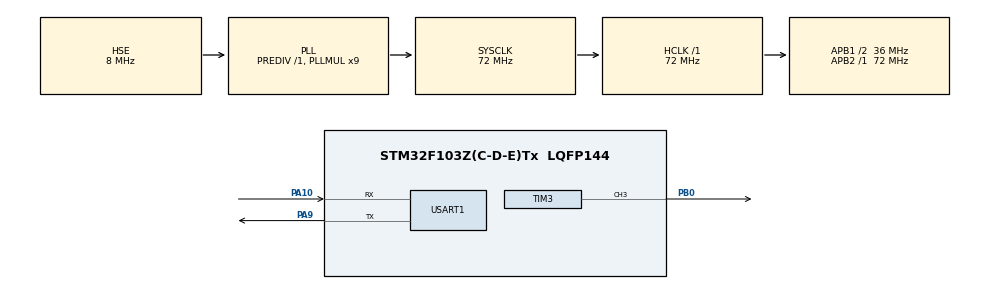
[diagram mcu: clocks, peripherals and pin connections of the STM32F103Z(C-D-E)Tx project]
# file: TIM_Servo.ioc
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Mcu.Family=STM32F1
Mcu.Name=STM32F103Z(C-D-E)Tx
Mcu.Package=LQFP144
NVIC.PriorityGroup=NVIC_PRIORITYGROUP_4
OSC_IN.Mode=HSE-External-Oscillator
OSC_IN.Signal=RCC_OSC_IN
OSC_OUT.Mode=HSE-External-Oscillator
OSC_OUT.Signal=RCC_OSC_OUT
PA10.Mode=Asynchronous
PA10.Signal=USART1_RX
PA13.Mode=Serial_Wire
PA13.Signal=SYS_JTMS-SWDIO
PA14.Mode=Serial_Wire
PA14.Signal=SYS_JTCK-SWCLK
PA9.Mode=Asynchronous
PA9.Signal=USART1_TX
PB0.Signal=S_TIM3_CH3
ProjectManager.HeapSize=0x200
ProjectManager.StackSize=0x400
ProjectManager.TargetToolchain=MDK-ARM V5.32
RCC.AHBFreq_Value=72000000
RCC.APB1CLKDivider=RCC_HCLK_DIV2
RCC.APB1Freq_Value=36000000
RCC.APB1TimFreq_Value=72000000
RCC.APB2Freq_Value=72000000
RCC.APB2TimFreq_Value=72000000
RCC.HCLKFreq_Value=72000000
RCC.PLLMUL=RCC_PLL_MUL9
RCC.PLLSourceVirtual=RCC_PLLSOURCE_HSE
RCC.SYSCLKFreq_VALUE=72000000
RCC.SYSCLKSource=RCC_SYSCLKSOURCE_PLLCLK
RCC.USBFreq_Value=72000000
SH.S_TIM3_CH3.0=TIM3_CH3,PWM Generation3 CH3
TIM3.Channel-PWM\ Generation3\ CH3=TIM_CHANNEL_3
TIM3.Period=20000-1
TIM3.Prescaler=72-1
TIM3.Pulse-PWM\ Generation3\ CH3=500
USART1.VirtualMode=VM_ASYNC
VP_TIM3_VS_ClockSourceINT.Mode=Internal
board=custom

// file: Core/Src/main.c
/* USER CODE BEGIN Header */
/**
  ******************************************************************************
  * @file           : main.c
  * @brief          : Main program body
  ******************************************************************************
  * @attention
  *
  * Copyright (c) 2025 STMicroelectronics.
  * All rights reserved.
  *
  * This software is licensed under terms that can be found in the LICENSE file
  * in the root directory of this software component.
  * If no LICENSE file comes with this software, it is provided AS-IS.
  *
  ******************************************************************************
  */
/* USER CODE END Header */
#include "main.h"

/* USER CODE BEGIN PD */
//#define COUNT_MAX 20
/* USER CODE END PD */

TIM_HandleTypeDef htim3;

UART_HandleTypeDef huart1;

void SystemClock_Config(void);
static void MX_GPIO_Init(void);
static void MX_TIM3_Init(void);
static void MX_USART1_UART_Init(void);

int main(void)
{
  /* USER CODE BEGIN 1 */
int i=600;
  /* USER CODE END 1 */

  /* MCU Configuration--------------------------------------------------------*/

  /* Reset of all peripherals, Initializes the Flash interface and the Systick. */
  HAL_Init();

  /* Configure the system clock */
  SystemClock_Config();

  /* Initialize all configured peripherals */
  MX_GPIO_Init();
  MX_TIM3_Init();
  MX_USART1_UART_Init();
  /* USER CODE BEGIN 2 */

HAL_TIM_PWM_Start(&htim3,TIM_CHANNEL_3);//Ӵ~�����ˣ���ס���𣿿�������

  /* USER CODE END 2 */

  /* Infinite loop */
  /* USER CODE BEGIN WHILE */
  while (1)
  {
//		__HAL_TIM_SET_COMPARE(&htim3,TIM_CHANNEL_3,500);
//				HAL_Delay(1000);
//		__HAL_TIM_SET_COMPARE(&htim3,TIM_CHANNEL_3,1000);
//				HAL_Delay(1000);
//		__HAL_TIM_SET_COMPARE(&htim3,TIM_CHANNEL_3,1500);
//				HAL_Delay(1000);
//		__HAL_TIM_SET_COMPARE(&htim3,TIM_CHANNEL_3,2000);
//				HAL_Delay(1000);
//		__HAL_TIM_SET_COMPARE(&htim3,TIM_CHANNEL_3,1500);
//				HAL_Delay(1000);
//		__HAL_TIM_SET_COMPARE(&htim3,TIM_CHANNEL_3,1000);
//				HAL_Delay(1000);
//		__HAL_TIM_SET_COMPARE(&htim3,TIM_CHANNEL_3,500);
//				HAL_Delay(1000);
	for(i=500;i<2400;i+=100)
	{
		__HAL_TIM_SET_COMPARE(&htim3,TIM_CHANNEL_3,i);
		HAL_Delay(100);
	}
	for(i=2500;i>600;i-=100)
	{
		__HAL_TIM_SET_COMPARE(&htim3,TIM_CHANNEL_3,i);
		HAL_Delay(100);
	}
    /* USER CODE END WHILE */

  }
}

void SystemClock_Config(void)
{
  RCC_OscInitTypeDef RCC_OscInitStruct = {0};
  RCC_ClkInitTypeDef RCC_ClkInitStruct = {0};

  /** Initializes the RCC Oscillators according to the specified parameters
  * in the RCC_OscInitTypeDef structure.
  */
  RCC_OscInitStruct.OscillatorType = RCC_OSCILLATORTYPE_HSE;
  RCC_OscInitStruct.HSEState = RCC_HSE_ON;
  RCC_OscInitStruct.HSEPredivValue = RCC_HSE_PREDIV_DIV1;
  RCC_OscInitStruct.HSIState = RCC_HSI_ON;
  RCC_OscInitStruct.PLL.PLLState = RCC_PLL_ON;
  RCC_OscInitStruct.PLL.PLLSource = RCC_PLLSOURCE_HSE;
  RCC_OscInitStruct.PLL.PLLMUL = RCC_PLL_MUL9;
  if (HAL_RCC_OscConfig(&RCC_OscInitStruct) != HAL_OK)
  {
    Error_Handler();
  }

  /** Initializes the CPU, AHB and APB buses clocks
  */
  RCC_ClkInitStruct.ClockType = RCC_CLOCKTYPE_HCLK|RCC_CLOCKTYPE_SYSCLK
                              |RCC_CLOCKTYPE_PCLK1|RCC_CLOCKTYPE_PCLK2;
  RCC_ClkInitStruct.SYSCLKSource = RCC_SYSCLKSOURCE_PLLCLK;
  RCC_ClkInitStruct.AHBCLKDivider = RCC_SYSCLK_DIV1;
  RCC_ClkInitStruct.APB1CLKDivider = RCC_HCLK_DIV2;
  RCC_ClkInitStruct.APB2CLKDivider = RCC_HCLK_DIV1;

  if (HAL_RCC_ClockConfig(&RCC_ClkInitStruct, FLASH_LATENCY_2) != HAL_OK)
  {
    Error_Handler();
  }
}

static void MX_TIM3_Init(void)
{

  TIM_ClockConfigTypeDef sClockSourceConfig = {0};
  TIM_MasterConfigTypeDef sMasterConfig = {0};
  TIM_OC_InitTypeDef sConfigOC = {0};

  htim3.Instance = TIM3;
  htim3.Init.Prescaler = 72-1;
  htim3.Init.CounterMode = TIM_COUNTERMODE_UP;
  htim3.Init.Period = 20000-1;
  htim3.Init.ClockDivision = TIM_CLOCKDIVISION_DIV1;
  htim3.Init.AutoReloadPreload = TIM_AUTORELOAD_PRELOAD_DISABLE;
  if (HAL_TIM_Base_Init(&htim3) != HAL_OK)
  {
    Error_Handler();
  }
  sClockSourceConfig.ClockSource = TIM_CLOCKSOURCE_INTERNAL;
  if (HAL_TIM_ConfigClockSource(&htim3, &sClockSourceConfig) != HAL_OK)
  {
    Error_Handler();
  }
  if (HAL_TIM_PWM_Init(&htim3) != HAL_OK)
  {
    Error_Handler();
  }
  sMasterConfig.MasterOutputTrigger = TIM_TRGO_RESET;
  sMasterConfig.MasterSlaveMode = TIM_MASTERSLAVEMODE_DISABLE;
  if (HAL_TIMEx_MasterConfigSynchronization(&htim3, &sMasterConfig) != HAL_OK)
  {
    Error_Handler();
  }
  sConfigOC.OCMode = TIM_OCMODE_PWM1;
  sConfigOC.Pulse = 500;
  sConfigOC.OCPolarity = TIM_OCPOLARITY_HIGH;
  sConfigOC.OCFastMode = TIM_OCFAST_DISABLE;
  if (HAL_TIM_PWM_ConfigChannel(&htim3, &sConfigOC, TIM_CHANNEL_3) != HAL_OK)
  {
    Error_Handler();
  }
  HAL_TIM_MspPostInit(&htim3);

}

static void MX_USART1_UART_Init(void)
{

  huart1.Instance = USART1;
  huart1.Init.BaudRate = 115200;
  huart1.Init.WordLength = UART_WORDLENGTH_8B;
  huart1.Init.StopBits = UART_STOPBITS_1;
  huart1.Init.Parity = UART_PARITY_NONE;
  huart1.Init.Mode = UART_MODE_TX_RX;
  huart1.Init.HwFlowCtl = UART_HWCONTROL_NONE;
  huart1.Init.OverSampling = UART_OVERSAMPLING_16;
  if (HAL_UART_Init(&huart1) != HAL_OK)
  {
    Error_Handler();
  }

}

static void MX_GPIO_Init(void)
{

  /* GPIO Ports Clock Enable */
  __HAL_RCC_GPIOB_CLK_ENABLE();
  __HAL_RCC_GPIOA_CLK_ENABLE();

}

void Error_Handler(void)
{
  __disable_irq();
  while (1)
  {
  }
}
